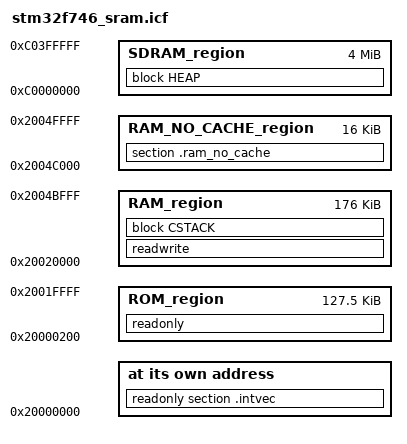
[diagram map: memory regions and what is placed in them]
/*###ICF### Section handled by ICF editor, don't touch! ****/
/*-Editor annotation file-*/
/* IcfEditorFile="$TOOLKIT_DIR$\config\ide\IcfEditor\cortex_v1_0.xml" */
/*-Specials-*/
define symbol __ICFEDIT_intvec_start__ = 0x20000000;
/*-Memory Regions-*/
define symbol __ICFEDIT_region_ROM_start__          = 0x20000200;
define symbol __ICFEDIT_region_ROM_end__            = 0x2001FFFF;
define symbol __ICFEDIT_region_RAM_start__          = 0x20020000;
define symbol __ICFEDIT_region_RAM_end__            = 0x2004BFFF;
define symbol __ICFEDIT_region_RAM_NO_CACHE_start__ = 0x2004C000;
define symbol __ICFEDIT_region_RAM_NO_CACHE_end__   = 0x2004FFFF;
define symbol __ICFEDIT_region_SDRAM_start__        = 0xC0000000;
define symbol __ICFEDIT_region_SDRAM_end__          = 0xC03FFFFF;
/*-Sizes-*/
define symbol __ICFEDIT_size_cstack__ = 0x400;
define symbol __ICFEDIT_size_heap__   = 0x100000;
/**** End of ICF editor section. ###ICF###*/

define memory mem with size  = 4G;
define region ROM_region          = mem:[from __ICFEDIT_region_ROM_start__          to __ICFEDIT_region_ROM_end__];
define region RAM_region          = mem:[from __ICFEDIT_region_RAM_start__          to __ICFEDIT_region_RAM_end__];
define region RAM_NO_CACHE_region = mem:[from __ICFEDIT_region_RAM_NO_CACHE_start__ to __ICFEDIT_region_RAM_NO_CACHE_end__];
define region SDRAM_region        = mem:[from __ICFEDIT_region_SDRAM_start__        to __ICFEDIT_region_SDRAM_end__];

define block CSTACK with alignment = 8, size = __ICFEDIT_size_cstack__   { };
define block HEAP   with alignment = 8, size = __ICFEDIT_size_heap__     { };

initialize by copy { readwrite };
do not initialize  { section .noinit };

place at address mem:__ICFEDIT_intvec_start__ { readonly section .intvec };

place in ROM_region { readonly };
place in RAM_region { readwrite, block CSTACK };
place in RAM_NO_CACHE_region { section .ram_no_cache };
place in SDRAM_region { block HEAP };
